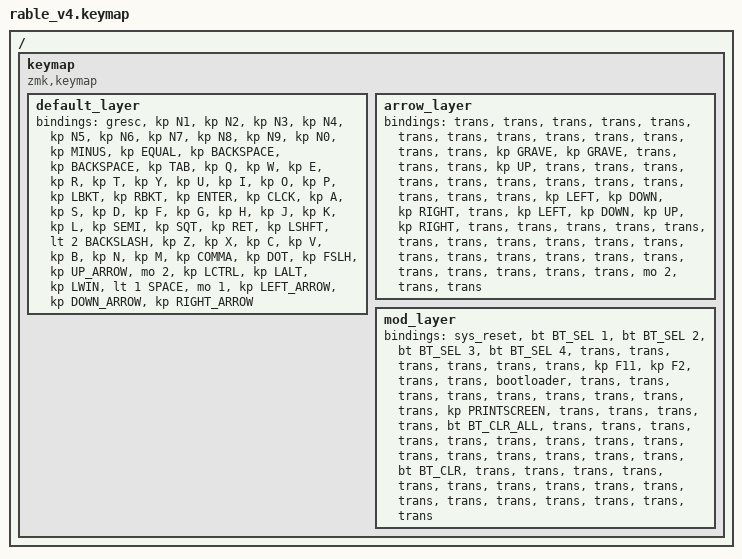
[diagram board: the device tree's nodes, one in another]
/*
 * Copyright (c) 2021 Nick Winans
 *
 * SPDX-License-Identifier: MIT
 */

#include <behaviors.dtsi>
#include <dt-bindings/zmk/bt.h>
#include <dt-bindings/zmk/keys.h>

/ {
    keymap {
        compatible = "zmk,keymap";

        default_layer {
            bindings = <
&gresc  &kp N1  &kp N2  &kp N3  &kp N4  &kp N5  &kp N6  &kp N7  &kp N8  &kp N9  &kp N0  &kp MINUS  &kp EQUAL  &kp BACKSPACE  &kp BACKSPACE  &kp TAB  &kp Q  &kp W  &kp E  &kp R  &kp T  &kp Y  &kp U  &kp I  &kp O  &kp P  &kp LBKT  &kp RBKT  &kp ENTER  &kp CLCK  &kp A  &kp S  &kp D  &kp F  &kp G  &kp H  &kp J  &kp K  &kp L  &kp SEMI  &kp SQT  &kp RET  &kp LSHFT  &lt 2 BACKSLASH  &kp Z  &kp X  &kp C  &kp V  &kp B  &kp N  &kp M  &kp COMMA  &kp DOT  &kp FSLH  &kp UP_ARROW  &mo 2  &kp LCTRL  &kp LALT  &kp LWIN  &lt 1 SPACE  &mo 1  &kp LEFT_ARROW  &kp DOWN_ARROW  &kp RIGHT_ARROW
            >;
        };

        arrow_layer {
            // ----------------------------------------------------------------------------------------------------------------
            // |        |    |     |     |     |     |     |     |     |     |     |     |     |     |     |   `~    |
            // |        |    |     |     |     |     |     |     |     |     |     |     |     |     |     |         |
            // |        |    |     |     |     |     |     |LEFT |DOWN |  UP |RIGHT|     |     |     |     |         |
            // |        |    |     |     |     |     |     |     |     |     |     |     |     |     |     |         |
            // |        |    |     |     |                                               |     |     |     |         |
            // ----------------------------------------------------------------------------------------------------------------

            bindings = <
&trans  &trans  &trans  &trans  &trans  &trans  &trans  &trans  &trans  &trans  &trans  &trans  &trans  &kp GRAVE  &kp GRAVE  &trans  &trans  &trans  &kp UP  &trans  &trans  &trans  &trans  &trans  &trans  &trans  &trans  &trans  &trans  &trans  &trans  &kp LEFT  &kp DOWN  &kp RIGHT  &trans  &kp LEFT  &kp DOWN  &kp UP  &kp RIGHT  &trans  &trans  &trans  &trans  &trans  &trans  &trans  &trans  &trans  &trans  &trans  &trans  &trans  &trans  &trans  &trans  &trans  &trans  &trans  &trans  &trans  &trans  &mo 2  &trans  &trans
            >;
        };

        mod_layer {
            // ----------------------------------------------------------------------------------------------------------------
            // |        |    | BT 1|BT 2 |BT 3 |BT 4 |     |     |     |     |     |     |     |     |BT CLR |         |
            // |        |    | RST | BOOT|     |     |     |     |     |     |     |     |     |     |       |         |
            // |        |    | USB | BLE |     |     |     |     |     |     |     |     |     |     |RGB TOG|         |
            // |        |    |EP_ON|EP_OFF|EP_TOG|     |     |     |     |     |     |     |     |     |       |         |
            // |        |    |     |     |                                               |     |     |       |         |
            // ----------------------------------------------------------------------------------------------------------------

            bindings = <
&sys_reset  &bt BT_SEL 1  &bt BT_SEL 2  &bt BT_SEL 3  &bt BT_SEL 4  &trans  &trans  &trans  &trans  &trans  &trans  &kp F11  &kp F2  &trans  &trans  &bootloader  &trans  &trans  &trans  &trans  &trans  &trans  &trans  &trans  &trans  &kp PRINTSCREEN  &trans  &trans  &trans  &trans  &bt BT_CLR_ALL  &trans  &trans  &trans  &trans  &trans  &trans  &trans  &trans  &trans  &trans  &trans  &trans  &trans  &trans  &trans  &bt BT_CLR  &trans  &trans  &trans  &trans  &trans  &trans  &trans  &trans  &trans  &trans  &trans  &trans  &trans  &trans  &trans  &trans  &trans
            >;
        };
    };
};
